# DSS_EDP0_INTG_CFG_VP register map
Vendor: Texas Instruments
Peripheral module from a debugger description file (folder J7ES).
Registers are 32-bit, read-write, reset 0x0 unless marked. A register's access mark holds for its fields unless they carry their own. Offsets are as the file gives them; lines under a group give offsets from that group; [hi:lo] are bit positions; {n}, {i} and the like mark numbered series; 'fields as' and 'values as' point back to an identical list; <NAME> marks a mode.

## DSS_EDP0_INTG_CFG_VP
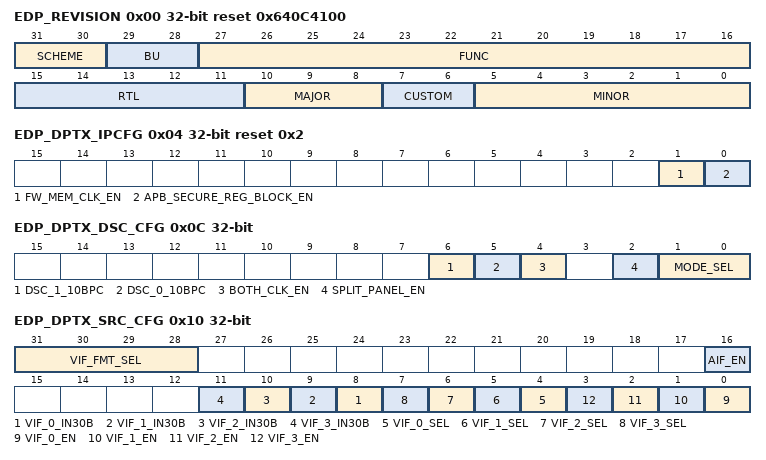
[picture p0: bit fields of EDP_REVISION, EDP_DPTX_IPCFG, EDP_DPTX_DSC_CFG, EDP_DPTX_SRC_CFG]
0x00 EDP_REVISION ro reset 0x640C4100 — The Register contains the major and minor revisions for the VPAC dptx HWA module.
  [31:30] SCHEME — Used to distinguish between old scheme and new scheme.
  [29:28] BU — BU indicator
  [27:16] FUNC — Function indicates a software compatible module family.
  [15:11] RTL — RTL Version.
  [10:8] MAJOR
  [7:6] CUSTOM — Indicates a special version for a particular device.
  [5:0] MINOR
0x04 EDP_DPTX_IPCFG reset 0x2 — The Register - Configures DPTX Core security mode and fw memory clock enable.
  [1] FW_MEM_CLK_EN — DPTX firmware memory (I/Dram) clock enable (set to 1 by default after a reset)
  [0] APB_SECURE_REG_BLOCK_EN — DPTX - APB secure region access block enable mode
0x08 EDP_ECC_MEM_CFG — The Register - Enables clocks to the ECC-aggregator/memories for ECC logic access. The setting of 1 forces the functional clock gating to be bypassed during memory ECC CTRL/Aggregator accesses during ECC diagnostic mode.
  [0] CLK_EN — Clk Force Enable for ECC access
0x0C EDP_DPTX_DSC_CFG — The Register - Configures DSC usaged of the DPTX Core. The settings are used by the wrapper to control the source clock gating for DSC sub-module and also to force enable vif memory clocks as necessary.
  [6] DSC_1_10BPC — DPTX - DSC encoder 1 - 10-bit input enable
  [5] DSC_0_10BPC — DPTX - DSC encoder 0 - 10-bit input enable
  [4] BOTH_CLK_EN — DPTX - DSC force both clock on whenever DSC is active
  [2] SPLIT_PANEL_EN — DPTX - DSC encoder mode select
  [1:0] MODE_SEL — DPTX - DSC encoder mode select
0x10 EDP_DPTX_SRC_CFG — The Register - Configures VIF and AIF port channel enables (for memory clock gating) and VIF source mux selection (for mapping DPI to VIF ports). The VIF_#_en also enables the clock for the # channel PIF memory. If a PIF channel is enabled, the vif_#_en must be set regardless of whether the associated video channel has the video enabled or not. Note that these settings are only used in the K3_DSS_eDP wrapper level (for controlling the memory clocks). The DPTX core requires separate configuration for enabling the video/audio streams for transmission. The enable settings between the core and wrapper should match for proper operation.
  [31:28] VIF_FMT_SEL — Reserved - must be set to 0
  [16] AIF_EN — DPTX Audio I2S channel memory clk enable
  [n+8] VIF_{n}_IN30B (n=0..3) — DPTX vif_{n} source data width is 30 bits
  [n+4] VIF_{n}_SEL (n=0..3) — DPTX vif_{n} source select - between dpi_{n} or dpi_{n+2}
  [n] VIF_{n}_EN (n=0..3) — DPTX vif_{n} channel memory clk enable
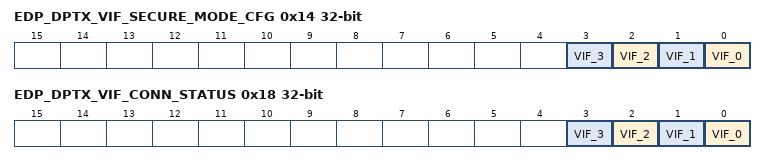
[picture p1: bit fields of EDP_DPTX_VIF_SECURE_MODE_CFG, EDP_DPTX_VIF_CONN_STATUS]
0x14 EDP_DPTX_VIF_SECURE_MODE_CFG — The Register - Configures the security level of the VIF channel (for protecting secure content from going to a non-protected display interface). When a VIF channel is configured as 'non-secure', the K3_DSS_eDP wrapper prevents secure DPI source data to be mapped to the VIF input. When this condition is detected, the wrapper forces the VIF source input to be 0x0. Therefore, if the DPI source from DSS is 'secure', then the mapped VIF channel must also be configured as 'secure'.
  [n] VIF_{n} (n=0..3) — vif_{n} channel secure mode:
0x18 EDP_DPTX_VIF_CONN_STATUS ro — The Register - Returns the status of DPI-VIF connection based on the security mode check. 0 indicates that the connection is allowed. 1 indicates that the connection is not allowed due to security setting mismatch. When a security mode mismatch is found on a VIF input channel, the source data signals for the channel are forced to 0 - resulting in black color output
  [n] VIF_{n} (n=0..3) — vif_0 security check status:
0x1C EDP_PHY_CLK_STATUS ro — The Register - Returns the current status of the phy data clock from DP phy. When the clock is not running, the ECC_aggr_PHY_cfg_regs will return 0x0 on a read
  [0] VALID — Phy Data Clock Valid Status
